# Cortex_M35P register map
Vendor: ARM Ltd.; Series: M
CPU: CM35 r0p0, little endian, vendor SysTick, 8 interrupt priority bits
Registers are 32-bit, read-write, no defined reset value unless marked. A register's access mark holds for its fields unless they carry their own. Offsets are from the block's base; lines under a group give offsets from that group; [hi:lo] are bit positions; {n}, {i} and the like mark numbered series; 'fields as' and 'values as' point back to an identical list; <NAME> marks a mode.

## Memory map
? Core — Core, the registers are not accessed by address
? FP — FP, the registers are not accessed by address
0xE000E004 ICB size 0x60 — Interrupt Control Registers
0xE000E010 SYST size 0x180 — SysTick Control Registers
0xE000E100 NVIC size 0x1B80 — Nested Vectored Interrupt Controller
0xE000ED00 SCB size 0x890 — System Control Block
0xE000ED90 MPU size 0x7E0 — Memory protection Unit Control Registers
0xE000EDD0 SAU size 0xE0 — Security Attribute Unit
0xE000EDF0 DCB size 0xC0 — Debug Registers
0xE000EF00 SIG size 0x20 — Software Interrupt Control
0xE000EF34 FPE size 0x180 — Floating Point Control Registers
0xE000EF50 CM size 0x140 — Cache Maintenance Operations
0xE000EFB0 DIB size 0x220 — Identification Registers

## Core — Core, the registers are not accessed by address
Base ?
? R{i} (i=0..12)
? SP
  [31:2] VALUE
? LR
  [31:0] VALUE
? PC
  [31:0] VALUE
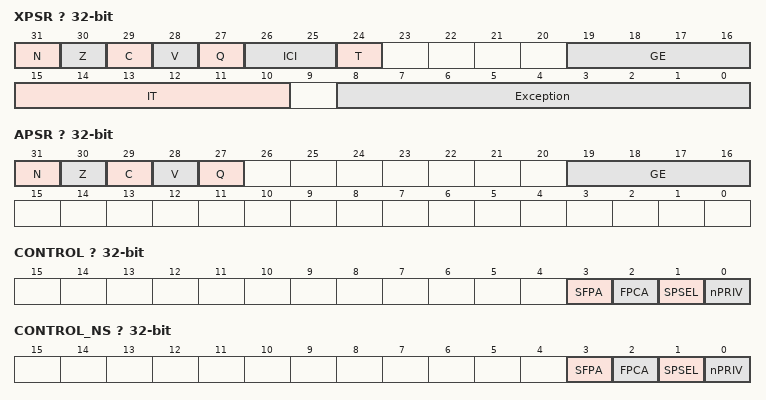
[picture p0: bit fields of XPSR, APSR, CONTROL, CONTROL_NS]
? XPSR
  [31] N
  [30] Z — Zero flag
  [29] C
  [28] V
  [27] Q
  [26:25] ICI
  [24] T — T32 state
  [19:16] GE
  [15:10] IT
  [8:0] Exception
? APSR
  [31] N, [30] Z, [29] C, [28] V, [27] Q, [19:16] GE
? BASEPRI
  [7:0] BASEPRI
? BASEPRI_NS
  [7:0] BASEPRI
? BASEPRI_S
  [7:0] BASEPRI
? CONTROL
  [3] SFPA, [2] FPCA, [1] SPSEL, [0] nPRIV
? CONTROL_NS
  [3] SFPA, [2] FPCA, [1] SPSEL, [0] nPRIV
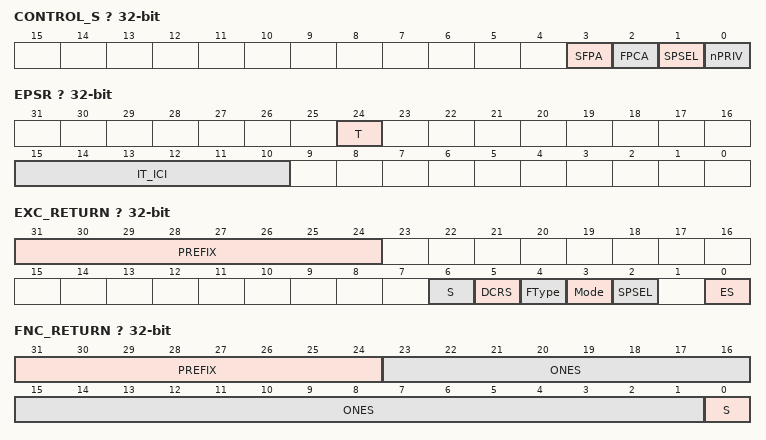
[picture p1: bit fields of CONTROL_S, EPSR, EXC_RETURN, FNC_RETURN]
? CONTROL_S
  [3] SFPA, [2] FPCA, [1] SPSEL, [0] nPRIV
? EPSR
  [24] T, [15:10] IT_ICI
? EXC_RETURN
  [31:24] PREFIX, [6] S, [5] DCRS, [4] FType, [3] Mode, [2] SPSEL, [0] ES
? FAULTMASK
  [0] FM
? FAULTMASK_NS
  [0] FM
? FAULTMASK_S
  [0] FM
? FNC_RETURN
  [31:24] PREFIX
  [23:1] ONES
  [0] S — Secure
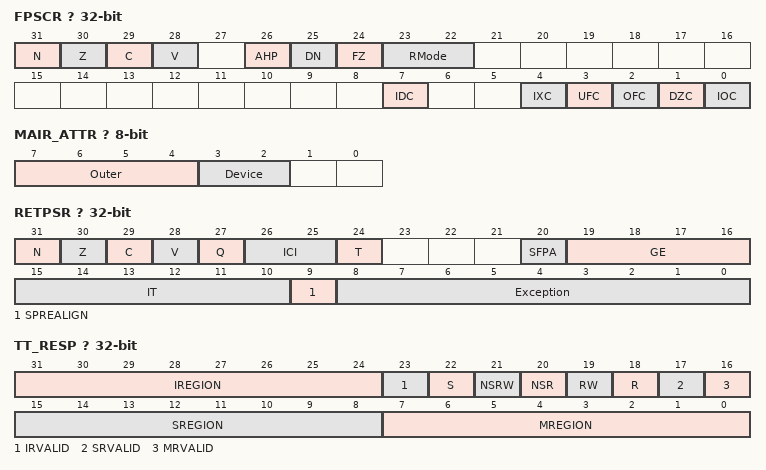
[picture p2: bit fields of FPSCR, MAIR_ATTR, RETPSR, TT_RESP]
? FPSCR
  [31] N, [30] Z, [29] C, [28] V, [26] AHP, [25] DN, [24] FZ, [23:22] RMode, [7] IDC, [4] IXC, [3] UFC, [2] OFC, [1] DZC, [0] IOC
? IPSR
  [8:0] Exception
? MAIR_ATTR 8-bit
  [7:4] Outer, [3:2] Device
? MSP
? MSPLIM
  [31:3] LIMIT
? MSPLIM_NS
  [31:3] LIMIT
? MSPLIM_S
  [31:3] LIMIT
? PRIMASK
  [0] PM
? PRIMASK_NS
  [0] PM
? PRIMASK_S
  [0] PM
? PSP
? PSPLIM
  [31:3] LIMIT
? PSPLIM_NS
  [31:3] LIMIT
? PSPLIM_S
  [31:3] LIMIT
? RETPSR
  [31] N
  [30] Z — Zero flag
  [29] C
  [28] V
  [27] Q
  [26:25] ICI
  [24] T — T32 state
  [20] SFPA
  [19:16] GE
  [15:10] IT
  [9] SPREALIGN
  [8:0] Exception
? SP_NS
  [31:2] VALUE
? TT_RESP
  [31:24] IREGION
  [23] IRVALID
  [22] S — Security
  [21] NSRW
  [20] NSR
  [19] RW
  [18] R — Readable
  [17] SRVALID
  [16] MRVALID
  [15:8] SREGION
  [7:0] MREGION

## FP — FP, the registers are not accessed by address
Base ?
? S{i} (i=0..31)
? D{i} 64-bit (i=0..15)

## FPE — Floating Point Control Registers
Base 0xE000EF34
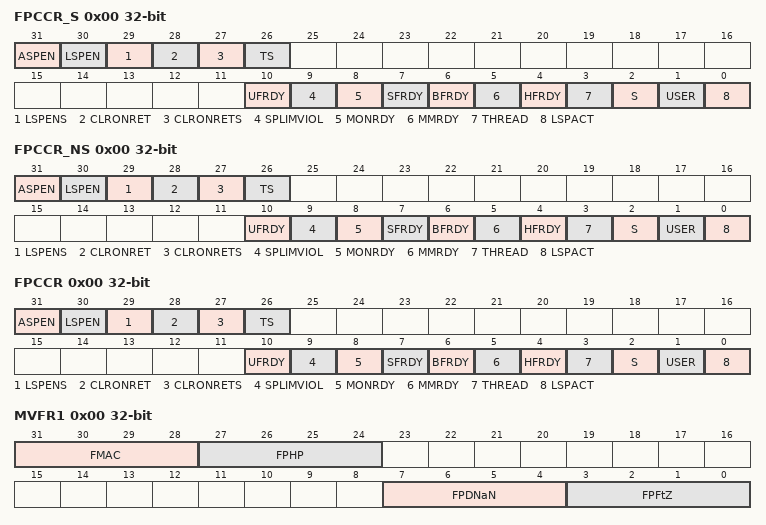
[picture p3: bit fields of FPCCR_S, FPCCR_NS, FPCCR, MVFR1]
0x00 FPCCR_S
  [31] ASPEN, [30] LSPEN, [29] LSPENS, [28] CLRONRET, [27] CLRONRETS, [26] TS, [10] UFRDY, [9] SPLIMVIOL, [8] MONRDY, [7] SFRDY, [6] BFRDY, [5] MMRDY, [4] HFRDY, [3] THREAD, [2] S, [1] USER, [0] LSPACT
0x00 FPCCR_NS
  fields as FPCCR_S
0x00 FPCCR
  fields as FPCCR_S
0x00 MVFR1 ro
  [31:28] FMAC, [27:24] FPHP, [7:4] FPDNaN, [3:0] FPFtZ
0x04 FPCAR_S
  [31:3] ADDRESS
0x04 FPCAR_NS
  [31:3] ADDRESS
0x04 FPCAR
  [31:3] ADDRESS
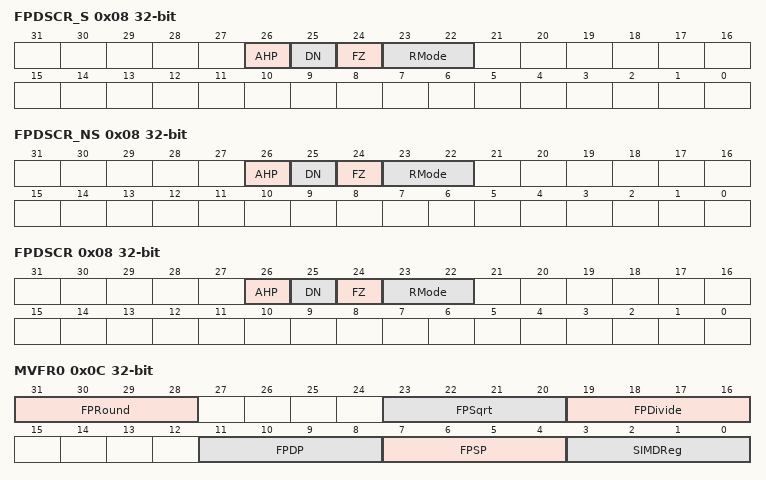
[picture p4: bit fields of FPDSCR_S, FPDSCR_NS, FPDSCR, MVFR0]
0x08 FPDSCR_S
  [26] AHP, [25] DN, [24] FZ, [23:22] RMode
0x08 FPDSCR_NS
  [26] AHP, [25] DN, [24] FZ, [23:22] RMode
0x08 FPDSCR
  [26] AHP, [25] DN, [24] FZ, [23:22] RMode
0x0C MVFR0 ro
  [31:28] FPRound, [23:20] FPSqrt, [19:16] FPDivide, [11:8] FPDP, [7:4] FPSP, [3:0] SIMDReg
0x14 MVFR2 ro
  [7:4] FPMisc

## CM — Cache Maintenance Operations
Base 0xE000EF50
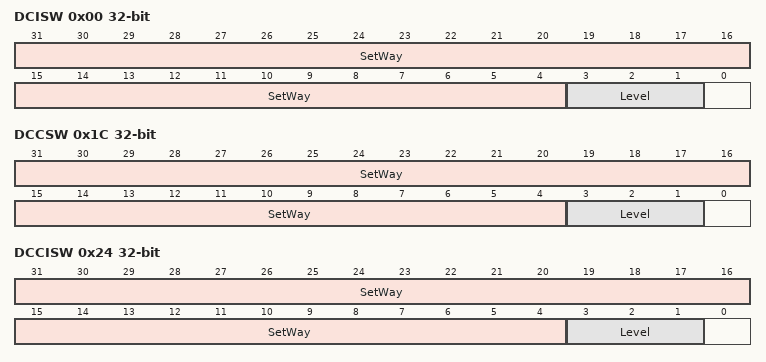
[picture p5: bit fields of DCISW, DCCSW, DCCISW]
0x00 DCISW wo
  [31:4] SetWay, [3:1] Level
0x00 ICIALLU wo
  [31:0] Ignored
0x08 ICIMVAU wo
  [31:0] ADDRESS
0x0C DCIMVAC wo
  [31:0] ADDRESS
0x14 DCCMVAU wo
  [31:0] ADDRESS
0x18 DCCMVAC wo
  [31:0] ADDRESS
0x1C DCCSW wo
  [31:4] SetWay, [3:1] Level
0x20 DCCIMVAC wo
  [31:0] ADDRESS
0x24 DCCISW wo
  [31:4] SetWay, [3:1] Level
0x28 BPIALL wo
  [31:0] Ignored
